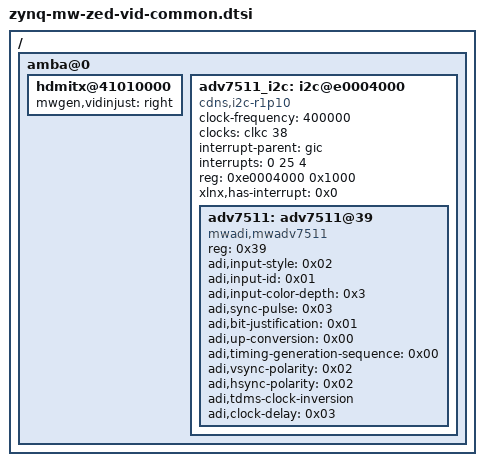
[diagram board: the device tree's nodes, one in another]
/include/ "zynq-mw-vid-common.dtsi"
/{

	amba@0{   
        hdmitx@41010000 {
	        mwgen,vidinjust = "right";
		};
		
		adv7511_i2c: i2c@e0004000 {
			clock-frequency = <400000>;
			clocks = <&clkc 38>;
			compatible = "cdns,i2c-r1p10";
			interrupt-parent = <&gic>;
			interrupts = <0 25 4>;
			reg = <0xe0004000 0x1000>;
			xlnx,has-interrupt = <0x0>;
			#address-cells = <1>;
			#size-cells = <0>;
			
			adv7511: adv7511@39 {
				compatible = "mwadi,mwadv7511";
				reg = <0x39>;

				adi,input-style = <0x02>;
				adi,input-id = <0x01>;
				adi,input-color-depth = <0x3>;
				adi,sync-pulse = <0x03>;
				adi,bit-justification = <0x01>;
				adi,up-conversion = <0x00>;
				adi,timing-generation-sequence = <0x00>;
				adi,vsync-polarity = <0x02>;
				adi,hsync-polarity = <0x02>;
				adi,tdms-clock-inversion;
				adi,clock-delay = <0x03>;
			};
		};
    };
};
